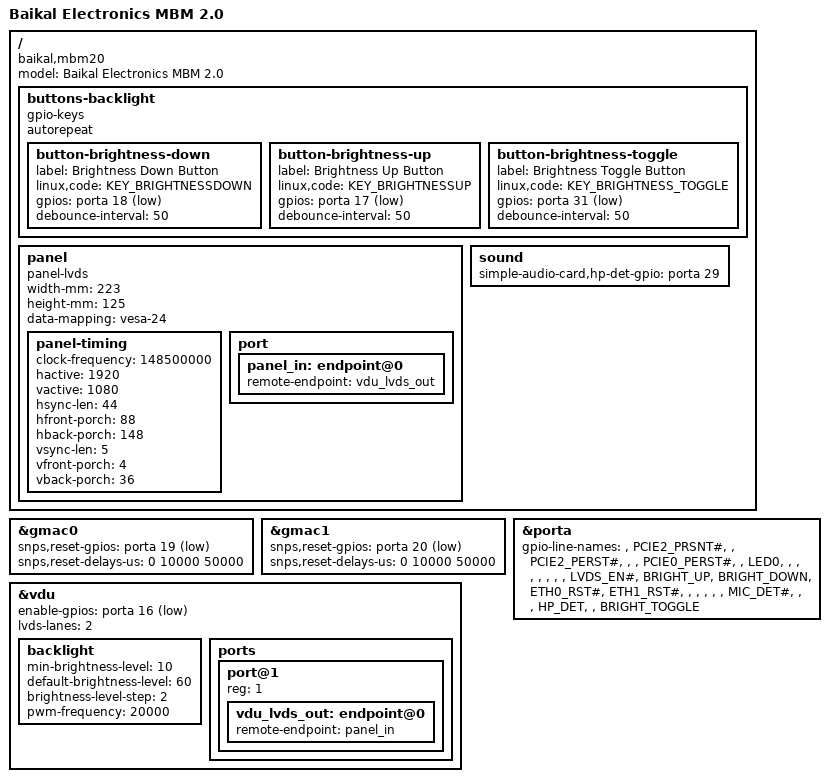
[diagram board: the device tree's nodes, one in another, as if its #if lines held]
// SPDX-License-Identifier: GPL-2.0
/*
 * Device tree source for MBM 2.0 compatible boards:
 *   - TF307-MB-S-D Rev.4.0 (BM1BM1-D)
 *
 * Copyright (C) 2021-2023 Baikal Electronics, JSC
 */

/dts-v1/;

#include <dt-bindings/input/input.h>
#include "bm1000-mbm.dtsi"

/ {
	model = "Baikal Electronics MBM 2.0";
	compatible = "baikal,mbm20", "baikal,bm1000";

#ifdef USE_LVDS
	buttons-backlight {
		compatible = "gpio-keys";
		autorepeat;
		button-brightness-down {
			label = "Brightness Down Button";
			linux,code = <KEY_BRIGHTNESSDOWN>;
			gpios = <&porta 18 GPIO_ACTIVE_LOW>;
			debounce-interval = <50>;
		};
		button-brightness-up {
			label = "Brightness Up Button";
			linux,code = <KEY_BRIGHTNESSUP>;
			gpios = <&porta 17 GPIO_ACTIVE_LOW>;
			debounce-interval = <50>;
		};
		button-brightness-toggle {
			label = "Brightness Toggle Button";
			linux,code = <KEY_BRIGHTNESS_TOGGLE>;
			gpios = <&porta 31 GPIO_ACTIVE_LOW>;
			debounce-interval = <50>;
		};
	};

	panel {
		compatible = "panel-lvds";
		width-mm = <223>;
		height-mm = <125>;
		data-mapping = "vesa-24";
		/*
		 * In order to utilize LVDS LCD panel, make sure that
		 * 'status' is "okay" along with &vdu 'status' (see below).
		 */
		status = "okay";
		panel-timing {
			/* 1920x1080 @ 60 Hz */
			/* Replace values below with actual panel timings */
			clock-frequency = <148500000>;
			hactive = <1920>;
			vactive = <1080>;
			hsync-len = <44>;
			hfront-porch = <88>;
			hback-porch = <148>;
			vsync-len = <5>;
			vfront-porch = <4>;
			vback-porch = <36>;
		};
		port {
			panel_in: endpoint@0 {
				remote-endpoint = <&vdu_lvds_out>;
			};
		};
	};
#endif
	sound {
		simple-audio-card,hp-det-gpio = <&porta 29 GPIO_ACTIVE_HIGH>;
	};
};

&gmac0 {
	snps,reset-gpios = <&porta 19 GPIO_ACTIVE_LOW>;
	snps,reset-delays-us = <0 10000 50000>;
};

&gmac1 {
	snps,reset-gpios = <&porta 20 GPIO_ACTIVE_LOW>;
	snps,reset-delays-us = <0 10000 50000>;
};

&porta {
	gpio-line-names =
		"",		/* GPIO32_0 */
		"PCIE2_PRSNT#",	/* GPIO32_1 */
		"",		/* GPIO32_2 */
		"PCIE2_PERST#",	/* GPIO32_3 */
		"",		/* GPIO32_4 */
		"",		/* GPIO32_5 */
		"PCIE0_PERST#",	/* GPIO32_6 */
		"",		/* GPIO32_7 */
		"LED0",		/* GPIO32_8 */
		"",		/* GPIO32_9 */
		"",		/* GPIO32_10 */
		"",		/* GPIO32_11 */
		"",		/* GPIO32_12 */
		"",		/* GPIO32_13 */
		"",		/* GPIO32_14 */
		"",		/* GPIO32_15 */
#ifdef USE_LVDS
		"LVDS_EN#",	/* GPIO32_16 */
#else
		"",		/* GPIO32_16 */
#endif
#ifdef USE_LVDS
		"BRIGHT_UP",	/* GPIO32_17 */
#else
		"LVDS_CLK_EN#", /* GPIO32_17 */
#endif
#ifdef USE_LVDS
		"BRIGHT_DOWN",	/* GPIO32_18 */
#else
		"HDMI_CLK_EN#",	/* GPIO32_18 */
#endif
		"ETH0_RST#",	/* GPIO32_19 */
		"ETH1_RST#",	/* GPIO32_20 */
		"",		/* GPIO32_21 */
		"",		/* GPIO32_22 */
		"",		/* GPIO32_23 */
		"",		/* GPIO32_24 */
		"",		/* GPIO32_25 */
		"MIC_DET#",	/* GPIO32_26 */
		"",		/* GPIO32_27 */
		"",		/* GPIO32_28 */
		"HP_DET",	/* GPIO32_29 */
		"",		/* GPIO32_30 */
#ifdef USE_LVDS
		"BRIGHT_TOGGLE";/* GPIO32_31 */
#else
		"";		/* GPIO32_31 */
#endif
};

#ifdef USE_LVDS
&vdu {
	/*
	 * 'lvds-lanes' property is mandatory to enable LVDS. Valid values are 1, 2 or 4.
	 * It is also mandatory to provide actual values for 'enable-gpios' property.
	 * Also make sure that panel's 'status' (see above) is "okay".
	 */
	enable-gpios = <&porta 16 GPIO_ACTIVE_LOW>;
	lvds-lanes = <2>;
	backlight {
		min-brightness-level = <10>;
		default-brightness-level = <60>;
		brightness-level-step = <2>;
		pwm-frequency = <20000>;
	};
	ports {
		port@1 {
			reg = <1>;
			vdu_lvds_out: endpoint@0 {
				remote-endpoint = <&panel_in>;
			};
		};
	};
};
#endif
